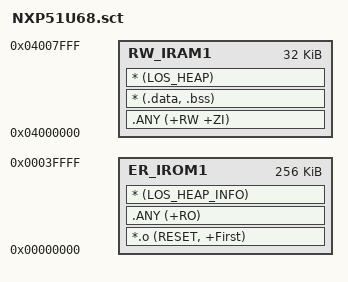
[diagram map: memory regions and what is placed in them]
; *************************************************************
; *** Scatter-Loading Description File generated by uVision ***
; *************************************************************

LR_IROM1 0x00000000 0x0040000  {    ; load region size_region
    ER_IROM1 0x000 0x00040000  {    ; load address = execution address
        *.o (RESET, +First)
        .ANY (+RO)
        * (LOS_HEAP_INFO)
    }
    RW_IRAM1 0x4000000 0x0008000  {    ; RW data
        .ANY (+RW +ZI)
        * (.data, .bss)
        * (LOS_HEAP)
    }
}

